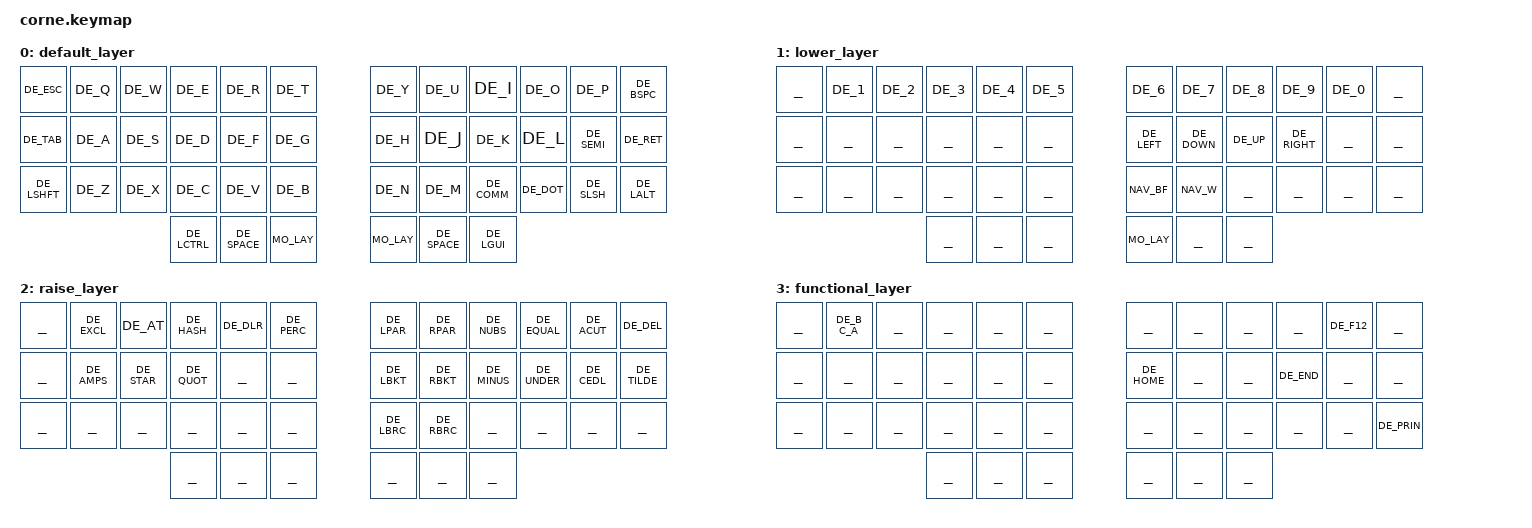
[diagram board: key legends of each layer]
/*
 * Copyright (c) 2020 The ZMK Contributors
 *
 * SPDX-License-Identifier: MIT
 */

#include <behaviors.dtsi>
#include <dt-bindings/zmk/keys.h>
#include <dt-bindings/zmk/bt.h>

#include "base_map/keymap_pt_br_abnt2_mac_zmk.h"
//#include "base_map/keymap_pt_br_lenovo_zmk.h"

/ {
        keymap {
                compatible = "zmk,keymap";

                default_layer {
      /*.------------------------------------------------.                         .-------------------------------------------------.
         |  ESC   |   Q   |   W   |   E   |   R   |   T   |                         |   Y   |   U   |   I   |   O   |   P   | BACKSPC |
         |--------+-------+-------+-------+-------+-------|                         |-------+-------+-------+-------+-------+---------|
         |  TAB   |   A   |   S   |   D   |   F   |   G   |                         |   H   |   J   |   K   |   L   |   ;   |   ENTER |
         |--------+-------+-------+-------+-------+-------|                         |-------+-------+-------+-------+-------+---------|
         |  ALT   |   Z   |   X   |   C   |   V   |   B   |                         |   N   |   M   |   ,   |   .   |   /   |   SHIFT |
         '---------------------------------------------------------|       |----------------------------------------------------------'
                                  |  CTRL    |  SPC       |   LWR  |       |  RIS   | SPC        |   GUI    |
                                  '--------------------------------'       '----------------------------------'*/

         bindings = <
	 DE_ESC    DE_Q    DE_W    DE_E    DE_R    DE_T                              DE_Y    DE_U     DE_I    DE_O    DE_P    DE_BSPC
	 DE_TAB    DE_A    DE_S    DE_D    DE_F    DE_G                              DE_H    DE_J     DE_K    DE_L    DE_SEMI DE_RET
	 DE_LSHFT  DE_Z    DE_X    DE_C    DE_V    DE_B                              DE_N    DE_M     DE_COMM DE_DOT  DE_SLSH DE_LALT
                                   DE_LCTRL   DE_SPACE      MO_LAY 1        MO_LAY 2 DE_SPACE     DE_LGUI
                        >;
                };
                lower_layer {
      /*.------------------------------------------------.                         .-------------------------------------------------.
         |        |   1   |   2   |   3   |   4   |   5   |                         |   6   |   7   |   8   |   9   |   0   |         |
         |--------+-------+-------+-------+-------+-------|                         |-------+-------+-------+-------+-------+---------|
         |        |       |       |       |       |       |                         |  LEFT |  DOWN |  UP   | RIGHT |       |         |
         |--------+-------+-------+-------+-------+-------|                         |-------+-------+-------+-------+-------+---------|
         |        |       |       |       |       |       |                         | nav_bf| nav_w |       |       |       |         |
         '---------------------------------------------------------|       |----------------------------------------------------------'
                                  |          |            |        |       |   FUN  |            |          |
                                  '--------------------------------'       '----------------------------------'*/

         bindings = <
	 ___       DE_1     DE_2    DE_3    DE_4    DE_5                              DE_6    DE_7    DE_8    DE_9    DE_0    ___
	 ___       ___      ___     ___     ___     ___                               DE_LEFT DE_DOWN DE_UP   DE_RIGHT ___    ___ 
	 ___       ___      ___     ___     ___     ___                               NAV_BF  NAV_W   ___     ___     ___     ___
                                   ___        ___         ___               MO_LAY 3  ___          ___
                        >;
                };

                raise_layer {
      /*.------------------------------------------------.                         .-------------------------------------------------.
         |        |   !   |   @   |   #   |   $   |   %   |                         |   (   |   )   |   \   |   =   |   '   |  DELETE |
         |--------+-------+-------+-------+-------+-------|                         |-------+-------+-------+-------+-------+---------|
         |        |   &   |   *   |   '   |       |       |                         |   [   |   ]   |   -   |   _   |   ç   |    ~    |
         |--------+-------+-------+-------+-------+-------|                         |-------+-------+-------+-------+-------+---------|
         |        |       |       |       |       |       |                         |   {   |   }   |       |       |       |         |
         '---------------------------------------------------------|       |----------------------------------------------------------'
                                  |          |            |        |       |        |            |          |
                                  '--------------------------------'       '----------------------------------'*/

         bindings = <
	 ___       DE_EXCL DE_AT   DE_HASH DE_DLR  DE_PERC                           DE_LPAR DE_RPAR DE_NUBS  DE_EQUAL DE_ACUT  DE_DEL
	 ___       DE_AMPS DE_STAR DE_QUOT ___     ___                               DE_LBKT DE_RBKT DE_MINUS DE_UNDER DE_CEDL  DE_TILDE
	 ___       ___     ___     ___     ___     ___                               DE_LBRC DE_RBRC ___     ___      ___       ___
                                   ___        ___         ___               ___      ___          ___
                        >;
                };
                functional_layer {
      /*.------------------------------------------------.                         .-------------------------------------------------.
         |        |CLR_BT |       |       |       |       |                         |       |       |       |       |  F12  |         |
         |--------+-------+-------+-------+-------+-------|                         |-------+-------+-------+-------+-------+---------|
         |        |       |       |       |       |       |                         |  HOME |       |       |  END  |       |         |
         |--------+-------+-------+-------+-------+-------|                         |-------+-------+-------+-------+-------+---------|
         |        |       |       |       |       |       |                         |       |       |       |       |       |  PRINT  |
         '---------------------------------------------------------|       |----------------------------------------------------------'
                                  |          |            |        |       |        |            |          |
                                  '--------------------------------'       '----------------------------------'*/

         bindings = <
	 ___       DE_B_C_A ___     ___     ___     ___                              ___     ___     ___     ___      DE_F12    ___
	 ___       ___     ___     ___     ___     ___                               DE_HOME ___     ___     DE_END   ___       ___ 
	 ___       ___     ___     ___     ___     ___                               ___     ___     ___     ___      ___       DE_PRIN
                                   ___        ___         ___               ___      ___          ___
                        >;
                };
        };
};

